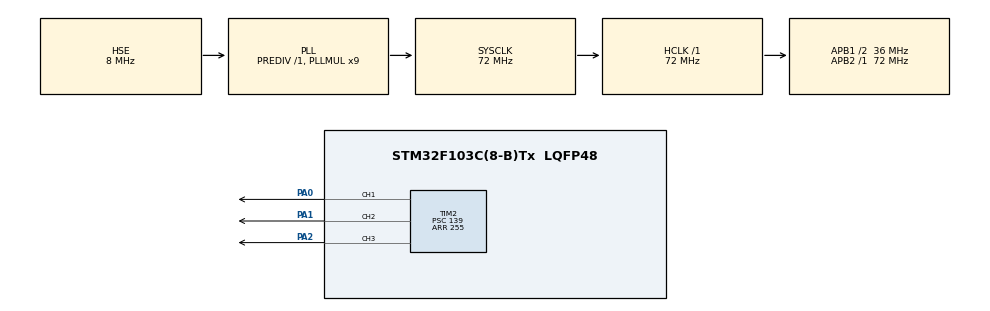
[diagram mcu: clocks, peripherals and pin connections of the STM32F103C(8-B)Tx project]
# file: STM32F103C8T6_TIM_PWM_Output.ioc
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Mcu.Family=STM32F1
Mcu.Name=STM32F103C(8-B)Tx
Mcu.Package=LQFP48
NVIC.PriorityGroup=NVIC_PRIORITYGROUP_4
PA0-WKUP.Signal=S_TIM2_CH1_ETR
PA1.Signal=S_TIM2_CH2
PA13.Mode=Serial_Wire
PA13.Signal=SYS_JTMS-SWDIO
PA14.Mode=Serial_Wire
PA14.Signal=SYS_JTCK-SWCLK
PA2.Signal=S_TIM2_CH3
PC14-OSC32_IN.Mode=LSE-External-Oscillator
PC14-OSC32_IN.Signal=RCC_OSC32_IN
PC15-OSC32_OUT.Mode=LSE-External-Oscillator
PC15-OSC32_OUT.Signal=RCC_OSC32_OUT
PD0-OSC_IN.Mode=HSE-External-Oscillator
PD0-OSC_IN.Signal=RCC_OSC_IN
PD1-OSC_OUT.Mode=HSE-External-Oscillator
PD1-OSC_OUT.Signal=RCC_OSC_OUT
ProjectManager.HeapSize=0x200
ProjectManager.StackSize=0x400
ProjectManager.TargetToolchain=STM32CubeIDE
RCC.AHBFreq_Value=72000000
RCC.APB1CLKDivider=RCC_HCLK_DIV2
RCC.APB1Freq_Value=36000000
RCC.APB1TimFreq_Value=72000000
RCC.APB2Freq_Value=72000000
RCC.APB2TimFreq_Value=72000000
RCC.EnbaleCSS=true
RCC.HCLKFreq_Value=72000000
RCC.PLLMUL=RCC_PLL_MUL9
RCC.PLLSourceVirtual=RCC_PLLSOURCE_HSE
RCC.SYSCLKFreq_VALUE=72000000
RCC.SYSCLKSource=RCC_SYSCLKSOURCE_PLLCLK
RCC.USBFreq_Value=72000000
SH.S_TIM2_CH1_ETR.0=TIM2_CH1,PWM Generation1 CH1
SH.S_TIM2_CH2.0=TIM2_CH2,PWM Generation2 CH2
SH.S_TIM2_CH3.0=TIM2_CH3,PWM Generation3 CH3
TIM2.Channel-PWM\ Generation1\ CH1=TIM_CHANNEL_1
TIM2.Channel-PWM\ Generation2\ CH2=TIM_CHANNEL_2
TIM2.Channel-PWM\ Generation3\ CH3=TIM_CHANNEL_3
TIM2.OCPolarity_1=TIM_OCPOLARITY_HIGH
TIM2.OCPolarity_2=TIM_OCPOLARITY_HIGH
TIM2.OCPolarity_3=TIM_OCPOLARITY_HIGH
TIM2.Period=255
TIM2.Prescaler=139
TIM2.Pulse-PWM\ Generation1\ CH1=0
TIM2.Pulse-PWM\ Generation2\ CH2=0
TIM2.Pulse-PWM\ Generation3\ CH3=0
TIM2.TIM_MasterOutputTrigger=TIM_TRGO_RESET
TIM2.TIM_MasterSlaveMode=TIM_MASTERSLAVEMODE_ENABLE
board=custom

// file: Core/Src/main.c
/* USER CODE BEGIN Header */
/**
  ******************************************************************************
  * @file           : main.c
  * @brief          : Main program body
  ******************************************************************************
  * @attention
  *
  * Copyright (c) 2026 STMicroelectronics.
  * All rights reserved.
  *
  * This software is licensed under terms that can be found in the LICENSE file
  * in the root directory of this software component.
  * If no LICENSE file comes with this software, it is provided AS-IS.
  *
  ******************************************************************************
  */
/* USER CODE END Header */
#include "main.h"
#include "tim.h"
#include "gpio.h"

void SystemClock_Config(void);
/* USER CODE BEGIN PFP */
typedef struct {
    uint8_t r;
    uint8_t g;
    uint8_t b;
} RGB_Color;

static void Set_Color_Palette(RGB_Color color);
/* USER CODE END PFP */

/* USER CODE BEGIN 0 */
// structure  RGB

// palette basic colors
RGB_Color palette[] = {
    {255,   0,   0}, // 1. Rouge
    {  0, 255,   0}, // 2. Vert
    {  0,   0, 255}, // 3. Bleu
    {255, 255,   0}, // 4. Jaune
    {  0, 255, 255}, // 5. Cyan
    {255,   0, 255}, // 6. Magenta
    {255, 255, 255}  // 7. Blanc
};

RGB_Color palette16[] = {
    {255,   0,   0}, // 1. Rouge
    {  0, 255,   0}, // 2. Vert
    {  0,   0, 255}, // 3. Bleu
    {255, 255,   0}, // 4. Jaune
    {  0, 255, 255}, // 5. Cyan
    {255,   0, 255}, // 6. Magenta
    {255, 255, 255}, // 7. Blanc Pur
    {255, 165,   0}, // 8. Orange
    {128,   0, 128}, // 9. Violet
    {255, 105, 180}, // 10. Rose (Hot Pink)
    {173, 216, 230}, // 11. Bleu Glace
    {255, 191,   0}, // 12. Ambre / Doré
    {152, 251, 152}, // 13. Vert Menthe
    {255, 127,  80}, // 14. Corail
    {  0, 102, 204}, // 15. Bleu Électrique
    {255, 244, 224}  // 16. Blanc Chaud
};

/* USER CODE END 0 */

int main(void)
{

  /* MCU Configuration--------------------------------------------------------*/

  /* Reset of all peripherals, Initializes the Flash interface and the Systick. */
  HAL_Init();

  /* Configure the system clock */
  SystemClock_Config();

  /* Initialize all configured peripherals */
  MX_GPIO_Init();
  MX_TIM2_Init();
  /* USER CODE BEGIN 2 */
  HAL_TIM_PWM_Start(&htim2, TIM_CHANNEL_1); // RED
  HAL_TIM_PWM_Start(&htim2, TIM_CHANNEL_2); // GREEN
  HAL_TIM_PWM_Start(&htim2, TIM_CHANNEL_3); // BLUE
  //HAL_TIM_PWM_Start(&htim2, TIM_CHANNEL_4);
  /* USER CODE END 2 */

  /* Infinite loop */
  while (1)
  {

    /* USER CODE BEGIN 3 */
	  uint8_t num_colors = sizeof(palette16) / sizeof(RGB_Color);
	  for (uint8_t i = 0; i < num_colors; i++)
	  	      {
		          Set_Color_Palette(palette16[i]);
	  	          HAL_Delay(2000);
	  	      }
	  	RGB_Color black = {0,0,0};
	  	Set_Color_Palette(black);

	  HAL_Delay(5000);
  }
  /* USER CODE END 3 */
}

void SystemClock_Config(void)
{
  RCC_OscInitTypeDef RCC_OscInitStruct = {0};
  RCC_ClkInitTypeDef RCC_ClkInitStruct = {0};

  /** Initializes the RCC Oscillators according to the specified parameters
  * in the RCC_OscInitTypeDef structure.
  */
  RCC_OscInitStruct.OscillatorType = RCC_OSCILLATORTYPE_HSE;
  RCC_OscInitStruct.HSEState = RCC_HSE_ON;
  RCC_OscInitStruct.HSEPredivValue = RCC_HSE_PREDIV_DIV1;
  RCC_OscInitStruct.HSIState = RCC_HSI_ON;
  RCC_OscInitStruct.PLL.PLLState = RCC_PLL_ON;
  RCC_OscInitStruct.PLL.PLLSource = RCC_PLLSOURCE_HSE;
  RCC_OscInitStruct.PLL.PLLMUL = RCC_PLL_MUL9;
  if (HAL_RCC_OscConfig(&RCC_OscInitStruct) != HAL_OK)
  {
    Error_Handler();
  }

  /** Initializes the CPU, AHB and APB buses clocks
  */
  RCC_ClkInitStruct.ClockType = RCC_CLOCKTYPE_HCLK|RCC_CLOCKTYPE_SYSCLK
                              |RCC_CLOCKTYPE_PCLK1|RCC_CLOCKTYPE_PCLK2;
  RCC_ClkInitStruct.SYSCLKSource = RCC_SYSCLKSOURCE_PLLCLK;
  RCC_ClkInitStruct.AHBCLKDivider = RCC_SYSCLK_DIV1;
  RCC_ClkInitStruct.APB1CLKDivider = RCC_HCLK_DIV2;
  RCC_ClkInitStruct.APB2CLKDivider = RCC_HCLK_DIV1;

  if (HAL_RCC_ClockConfig(&RCC_ClkInitStruct, FLASH_LATENCY_2) != HAL_OK)
  {
    Error_Handler();
  }

  /** Enables the Clock Security System
  */
  HAL_RCC_EnableCSS();
}

/* USER CODE BEGIN 4 */

static void Set_Color_Palette(RGB_Color color)
{
	__HAL_TIM_SET_COMPARE(&htim2, TIM_CHANNEL_1, color.r);
    __HAL_TIM_SET_COMPARE(&htim2, TIM_CHANNEL_2, color.g);
	__HAL_TIM_SET_COMPARE(&htim2, TIM_CHANNEL_3, color.b);
}

/* USER CODE END 4 */

void Error_Handler(void)
{
  __disable_irq();
  while (1)
  {
  }
}
